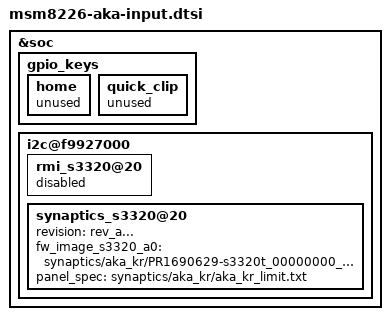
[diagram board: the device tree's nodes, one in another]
/* Copyright (c) 2013, LGE Electronics. All rights reserved.
 *
 * This program is free software; you can redistribute it and/or modify
 * it under the terms of the GNU General Public License version 2 and
 * only version 2 as published by the Free Software Foundation.
 *
 * This program is distributed in the hope that it will be useful,
 * but WITHOUT ANY WARRANTY; without even the implied warranty of
 * MERCHANTABILITY or FITNESS FOR A PARTICULAR PURPOSE.  See the
 * GNU General Public License for more details.
 */

&soc {
	gpio_keys {
		home {
			unused;
		};

		quick_clip {
			unused;
		};
	};

	i2c@f9927000 { /* BLSP1 QUP5 */
	    rmi_s3320@20  {
			status = "disable";
		};

		synaptics_s3320@20 {
			status = "ok";
			revision = "rev_a...";
				fw_image_s3320_a0 = "synaptics/aka_kr/PR1690629-s3320t_00000000_A208A.img";
				panel_spec = "synaptics/aka_kr/aka_kr_limit.txt";
		};

	};

};
